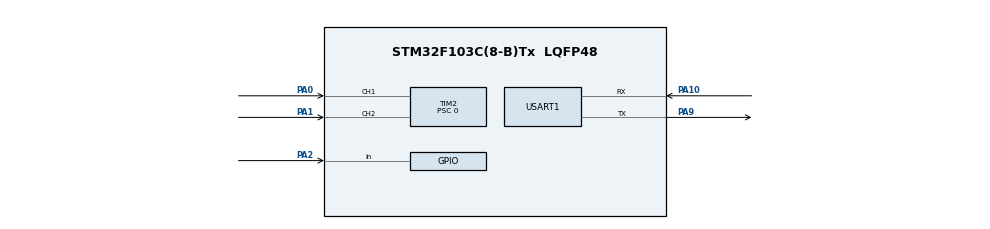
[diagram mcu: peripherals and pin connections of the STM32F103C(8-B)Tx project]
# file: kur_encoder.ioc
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Mcu.Family=STM32F1
Mcu.Name=STM32F103C(8-B)Tx
Mcu.Package=LQFP48
NVIC.PriorityGroup=NVIC_PRIORITYGROUP_4
PA0-WKUP.Signal=S_TIM2_CH1_ETR
PA1.Signal=S_TIM2_CH2
PA10.Mode=Asynchronous
PA10.Signal=USART1_RX
PA13.Mode=Serial_Wire
PA13.Signal=SYS_JTMS-SWDIO
PA14.Mode=Serial_Wire
PA14.Signal=SYS_JTCK-SWCLK
PA2.Signal=GPIO_Input
PA9.Mode=Asynchronous
PA9.Signal=USART1_TX
ProjectManager.HeapSize=0x200
ProjectManager.StackSize=0x400
ProjectManager.TargetToolchain=MDK-ARM V5
RCC.APB1Freq_Value=8000000
RCC.APB2Freq_Value=8000000
SH.S_TIM2_CH1_ETR.0=TIM2_CH1,Encoder_Interface
SH.S_TIM2_CH2.0=TIM2_CH2,Encoder_Interface
TIM2.AutoReloadPreload=TIM_AUTORELOAD_PRELOAD_ENABLE
TIM2.EncoderMode=TIM_ENCODERMODE_TI12
TIM2.IC2Filter=10
TIM2.Prescaler=0
USART1.VirtualMode=VM_ASYNC
board=custom

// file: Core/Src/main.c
/* USER CODE BEGIN Header */
/**
  ******************************************************************************
  * @file           : main.c
  * @brief          : Main program body
  ******************************************************************************
  * @attention
  *
  * <h2><center>&copy; Copyright (c) 2021 STMicroelectronics.
  * All rights reserved.</center></h2>
  *
  * This software component is licensed by ST under BSD 3-Clause license,
  * the "License"; You may not use this file except in compliance with the
  * License. You may obtain a copy of the License at:
  *                        opensource.org/licenses/BSD-3-Clause
  *
  ******************************************************************************
  */
/* USER CODE END Header */
#include "main.h"

/* USER CODE BEGIN Includes */
#include <stdio.h>
/* USER CODE END Includes */

/* USER CODE BEGIN PTD */
short tim_val;
/* USER CODE END PTD */

TIM_HandleTypeDef htim2;

UART_HandleTypeDef huart1;

void SystemClock_Config(void);
static void MX_GPIO_Init(void);
static void MX_TIM2_Init(void);
static void MX_USART1_UART_Init(void);

/* USER CODE BEGIN 0 */
_ARMABI int fputc(int c, FILE * stream)
{
	HAL_UART_Transmit(&huart1,(uint8_t*)&c,1,100);
	return 0;
}
/* USER CODE END 0 */

int main(void)
{
  /* USER CODE BEGIN 1 */
  volatile short encoder_cnt = 0;
  /* USER CODE END 1 */

  /* MCU Configuration--------------------------------------------------------*/

  /* Reset of all peripherals, Initializes the Flash interface and the Systick. */
  HAL_Init();

  /* Configure the system clock */
  SystemClock_Config();

  /* Initialize all configured peripherals */
  MX_GPIO_Init();
  MX_TIM2_Init();
  MX_USART1_UART_Init();
  /* USER CODE BEGIN 2 */
   HAL_TIM_Encoder_Start(&htim2, TIM_CHANNEL_1 | TIM_CHANNEL_2);
  /* USER CODE END 2 */

  /* Infinite loop */
  while (1)
  {

    /* USER CODE BEGIN 3 */
		tim_val = (__HAL_TIM_GET_COUNTER(&htim2))>>2   ;
		encoder_cnt = tim_val*360/20 ;
		if(HAL_GPIO_ReadPin(GPIOA,GPIO_PIN_2)==1)
   {

		 printf("R:%d°\r\n",encoder_cnt);
	 }

		else
   {

     	 printf("P:%d°\r\n",encoder_cnt);
	 }

		HAL_Delay(500);
  }
  /* USER CODE END 3 */
}

void SystemClock_Config(void)
{
  RCC_OscInitTypeDef RCC_OscInitStruct = {0};
  RCC_ClkInitTypeDef RCC_ClkInitStruct = {0};

  /** Initializes the RCC Oscillators according to the specified parameters
  * in the RCC_OscInitTypeDef structure.
  */
  RCC_OscInitStruct.OscillatorType = RCC_OSCILLATORTYPE_HSI;
  RCC_OscInitStruct.HSIState = RCC_HSI_ON;
  RCC_OscInitStruct.HSICalibrationValue = RCC_HSICALIBRATION_DEFAULT;
  RCC_OscInitStruct.PLL.PLLState = RCC_PLL_NONE;
  if (HAL_RCC_OscConfig(&RCC_OscInitStruct) != HAL_OK)
  {
    Error_Handler();
  }
  /** Initializes the CPU, AHB and APB buses clocks
  */
  RCC_ClkInitStruct.ClockType = RCC_CLOCKTYPE_HCLK|RCC_CLOCKTYPE_SYSCLK
                              |RCC_CLOCKTYPE_PCLK1|RCC_CLOCKTYPE_PCLK2;
  RCC_ClkInitStruct.SYSCLKSource = RCC_SYSCLKSOURCE_HSI;
  RCC_ClkInitStruct.AHBCLKDivider = RCC_SYSCLK_DIV1;
  RCC_ClkInitStruct.APB1CLKDivider = RCC_HCLK_DIV1;
  RCC_ClkInitStruct.APB2CLKDivider = RCC_HCLK_DIV1;

  if (HAL_RCC_ClockConfig(&RCC_ClkInitStruct, FLASH_LATENCY_0) != HAL_OK)
  {
    Error_Handler();
  }
}

static void MX_TIM2_Init(void)
{

  TIM_Encoder_InitTypeDef sConfig = {0};
  TIM_MasterConfigTypeDef sMasterConfig = {0};

  htim2.Instance = TIM2;
  htim2.Init.Prescaler = 0;
  htim2.Init.CounterMode = TIM_COUNTERMODE_UP;
  htim2.Init.Period = 65535;
  htim2.Init.ClockDivision = TIM_CLOCKDIVISION_DIV1;
  htim2.Init.AutoReloadPreload = TIM_AUTORELOAD_PRELOAD_ENABLE;
  sConfig.EncoderMode = TIM_ENCODERMODE_TI12;
  sConfig.IC1Polarity = TIM_ICPOLARITY_RISING;
  sConfig.IC1Selection = TIM_ICSELECTION_DIRECTTI;
  sConfig.IC1Prescaler = TIM_ICPSC_DIV1;
  sConfig.IC1Filter = 0;
  sConfig.IC2Polarity = TIM_ICPOLARITY_RISING;
  sConfig.IC2Selection = TIM_ICSELECTION_DIRECTTI;
  sConfig.IC2Prescaler = TIM_ICPSC_DIV1;
  sConfig.IC2Filter = 10;
  if (HAL_TIM_Encoder_Init(&htim2, &sConfig) != HAL_OK)
  {
    Error_Handler();
  }
  sMasterConfig.MasterOutputTrigger = TIM_TRGO_RESET;
  sMasterConfig.MasterSlaveMode = TIM_MASTERSLAVEMODE_DISABLE;
  if (HAL_TIMEx_MasterConfigSynchronization(&htim2, &sMasterConfig) != HAL_OK)
  {
    Error_Handler();
  }

}

static void MX_USART1_UART_Init(void)
{

  huart1.Instance = USART1;
  huart1.Init.BaudRate = 115200;
  huart1.Init.WordLength = UART_WORDLENGTH_8B;
  huart1.Init.StopBits = UART_STOPBITS_1;
  huart1.Init.Parity = UART_PARITY_NONE;
  huart1.Init.Mode = UART_MODE_TX_RX;
  huart1.Init.HwFlowCtl = UART_HWCONTROL_NONE;
  huart1.Init.OverSampling = UART_OVERSAMPLING_16;
  if (HAL_UART_Init(&huart1) != HAL_OK)
  {
    Error_Handler();
  }

}

static void MX_GPIO_Init(void)
{
  GPIO_InitTypeDef GPIO_InitStruct = {0};

  /* GPIO Ports Clock Enable */
  __HAL_RCC_GPIOA_CLK_ENABLE();

  /*Configure GPIO pin : PA2 */
  GPIO_InitStruct.Pin = GPIO_PIN_2;
  GPIO_InitStruct.Mode = GPIO_MODE_INPUT;
  GPIO_InitStruct.Pull = GPIO_NOPULL;
  HAL_GPIO_Init(GPIOA, &GPIO_InitStruct);

}

void Error_Handler(void)
{
  __disable_irq();
  while (1)
  {
  }
}

/************************ (C) COPYRIGHT STMicroelectronics *****END OF FILE****/
